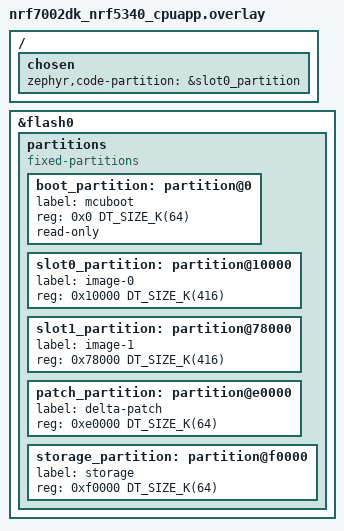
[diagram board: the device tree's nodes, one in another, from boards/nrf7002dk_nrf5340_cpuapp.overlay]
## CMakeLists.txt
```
# SPDX-License-Identifier: Apache-2.0

cmake_minimum_required(VERSION 3.20.0)

find_package(Zephyr REQUIRED HINTS $ENV{ZEPHYR_BASE})
project(delta)

target_sources(app PRIVATE src/main.c)
target_sources_ifndef(CONFIG_DELTA_SAMPLE_TARGET_MODE app PRIVATE src/delta_apply.c)

# flash_patch target: convert a patch binary to Intel HEX at the
# devicetree-resolved patch_partition address and flash it.
dt_nodelabel(patch_path NODELABEL "patch_partition")
if(DEFINED patch_path)
  dt_reg_addr(patch_offset PATH ${patch_path})

  math(EXPR PATCH_FLASH_ADDR
       "${CONFIG_FLASH_BASE_ADDRESS} + ${patch_offset}"
       OUTPUT_FORMAT HEXADECIMAL)

  set(PATCH_FILE ${CMAKE_CURRENT_SOURCE_DIR}/firmwares/patch.bin
      CACHE FILEPATH "Path to the delta patch binary to flash")

  find_program(WEST west REQUIRED)

  add_custom_target(flash_patch
      COMMAND ${CMAKE_OBJCOPY} -I binary -O ihex
              --change-addresses ${PATCH_FLASH_ADDR}
              ${PATCH_FILE}
              ${PROJECT_BINARY_DIR}/patch.hex
      COMMAND ${WEST} flash --hex-file ${PROJECT_BINARY_DIR}/patch.hex
      COMMENT "Flashing delta patch to patch_partition at ${PATCH_FLASH_ADDR}"
      USES_TERMINAL
  )
endif()
```

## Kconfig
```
# Copyright (c) 2026 Clovis Corde
# SPDX-License-Identifier: Apache-2.0

mainmenu "Delta Firmware Update Sample"

source "Kconfig.zephyr"

config DELTA_SAMPLE_TARGET_MODE
	bool "Build as the target firmware for delta patch generation"
	help
	  When enabled, the application simply prints a message and
	  exits without applying any delta patch. This is used to
	  produce the target firmware binary needed by
	  generate_patch.py to compute the delta between the source
	  and target images.
```

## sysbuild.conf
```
SB_CONFIG_BOOTLOADER_MCUBOOT=y
SB_CONFIG_MCUBOOT_MODE_SWAP_USING_MOVE=y
```

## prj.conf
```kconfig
# Logging
CONFIG_LOG=y
CONFIG_LOG_MODE_DEFERRED=y

CONFIG_MAIN_STACK_SIZE=8192
CONFIG_REBOOT=y

# Flash / MCUboot
CONFIG_FLASH=y
CONFIG_FLASH_MAP=y
CONFIG_STREAM_FLASH=y
CONFIG_IMG_MANAGER=y
CONFIG_MCUBOOT_IMG_MANAGER=y
CONFIG_BOOTLOADER_MCUBOOT=y
CONFIG_IMG_BLOCK_BUF_SIZE=512

# Delta patching library + bsdiff/heatshrink backend
CONFIG_DELTA=y
CONFIG_DELTA_BACKEND_BSDIFFHS=y
CONFIG_DELTA_LOG_LEVEL_INF=y

# heatshrink in static-allocation mode; the patch must declare a
# window_sz2 and lookahead_sz2 with these values.
CONFIG_HEATSHRINK=y
CONFIG_HEATSHRINK_STATIC_WINDOW_BITS=10
CONFIG_HEATSHRINK_STATIC_LOOKAHEAD_BITS=4
CONFIG_HEATSHRINK_STATIC_INPUT_BUFFER_SIZE=64
```

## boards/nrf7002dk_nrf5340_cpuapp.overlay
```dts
/*
 * Copyright (c) 2026 Clovis Corde
 * SPDX-License-Identifier: Apache-2.0
 */

/ {
	chosen {
		zephyr,code-partition = &slot0_partition;
	};
};

&flash0 {
	/delete-node/ partitions;

	partitions {
		compatible = "fixed-partitions";
		#address-cells = <1>;
		#size-cells = <1>;

		boot_partition: partition@0 {
			label = "mcuboot";
			reg = <0x0 DT_SIZE_K(64)>;
			read-only;
		};

		slot0_partition: partition@10000 {
			label = "image-0";
			reg = <0x10000 DT_SIZE_K(416)>;
		};

		slot1_partition: partition@78000 {
			label = "image-1";
			reg = <0x78000 DT_SIZE_K(416)>;
		};

		patch_partition: partition@e0000 {
			label = "delta-patch";
			reg = <0xe0000 DT_SIZE_K(64)>;
		};

		storage_partition: partition@f0000 {
			label = "storage";
			reg = <0xf0000 DT_SIZE_K(64)>;
		};
	};
};
```

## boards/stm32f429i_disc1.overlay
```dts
/*
 * Copyright (c) 2026 Clovis Corde
 * SPDX-License-Identifier: Apache-2.0
 */

/ {
	chosen {
		zephyr,code-partition = &slot0_partition;
	};
};

&flash0 {
	partitions {
		compatible = "fixed-partitions";
		#address-cells = <1>;
		#size-cells = <1>;

		boot_partition: partition@0 {
			label = "mcuboot";
			reg = <0x0 DT_SIZE_K(128)>;
			read-only;
		};

		slot0_partition: partition@20000 {
			label = "image-0";
			reg = <0x20000 DT_SIZE_K(384)>;
		};

		slot1_partition: partition@80000 {
			label = "image-1";
			reg = <0x80000 DT_SIZE_K(384)>;
		};

		patch_partition: partition@120000 {
			label = "delta-patch";
			reg = <0x120000 DT_SIZE_K(128)>;
		};
	};
};
```

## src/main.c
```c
/*
 * Copyright (c) 2026 Clovis Corde
 *
 * SPDX-License-Identifier: Apache-2.0
 */

#include <zephyr/kernel.h>
#include <zephyr/logging/log.h>

#if !defined(CONFIG_DELTA_SAMPLE_TARGET_MODE)
#include "delta_apply.h"
#endif

LOG_MODULE_REGISTER(delta_sample, LOG_LEVEL_INF);

int main(void)
{
#if defined(CONFIG_DELTA_SAMPLE_TARGET_MODE)
	LOG_INF("Delta target firmware");
	return 0;
#else
	int ret;

	LOG_INF("Delta sample");

	ret = delta_apply_and_reboot();
	if (ret != 0) {
		LOG_ERR("Error while applying delta update: %d", ret);
	}

	return ret;
#endif
}
```

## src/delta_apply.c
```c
/*
 * Copyright (c) 2026 Clovis Corde
 *
 * SPDX-License-Identifier: Apache-2.0
 */

#include <zephyr/delta/delta.h>
#include <zephyr/delta/backend_bsdiffhs.h>
#include <zephyr/dfu/flash_img.h>
#include <zephyr/dfu/mcuboot.h>
#include <zephyr/kernel.h>
#include <zephyr/logging/log.h>
#include <zephyr/logging/log_ctrl.h>
#include <zephyr/storage/flash_map.h>
#include <zephyr/sys/reboot.h>
#include <zephyr/sys/util.h>

#include "delta_apply.h"

LOG_MODULE_REGISTER(delta_apply, LOG_LEVEL_INF);

/* Glue between lib/delta and the MCUboot flash layout. */
struct delta_ctx {
	const struct flash_area *source_area;
	const struct flash_area *patch_area;
	struct flash_img_context flash_img;
};

/* Patch read-ahead window handed to the backend. */
#define WORK_BUF_SIZE 128

static uint8_t work_buf[WORK_BUF_SIZE];

static int read_source(void *vctx, size_t off, void *buf, size_t len)
{
	struct delta_ctx *ctx = vctx;

	return flash_area_read(ctx->source_area, (off_t)off, buf, len);
}

static int read_patch(void *vctx, size_t off, void *buf, size_t len)
{
	struct delta_ctx *ctx = vctx;

	return flash_area_read(ctx->patch_area, (off_t)off, buf, len);
}

static int write_target(void *vctx, size_t off, const void *buf, size_t len)
{
	struct delta_ctx *ctx = vctx;

	ARG_UNUSED(off);
	return flash_img_buffered_write(&ctx->flash_img, buf, len, false);
}

static int finalize_target(void *vctx)
{
	struct delta_ctx *ctx = vctx;

	/* Flush the last partially filled block to the upload slot. */
	return flash_img_buffered_write(&ctx->flash_img, NULL, 0, true);
}

int delta_apply_and_reboot(void)
{
	struct delta_ctx ctx;
	int ret;

	ret = flash_area_open(PARTITION_ID(slot0_partition), &ctx.source_area);
	if (ret != 0) {
		LOG_ERR("flash_area_open(slot0) failed: %d", ret);
		return ret;
	}

	ret = flash_area_open(PARTITION_ID(patch_partition), &ctx.patch_area);
	if (ret != 0) {
		LOG_ERR("flash_area_open(patch) failed: %d", ret);
		flash_area_close(ctx.source_area);
		return ret;
	}

	ret = flash_img_init(&ctx.flash_img);
	if (ret != 0) {
		LOG_ERR("flash_img_init failed: %d", ret);
		flash_area_close(ctx.patch_area);
		flash_area_close(ctx.source_area);
		return ret;
	}

	struct delta_io io = {
		.read_source = read_source,
		.read_patch = read_patch,
		.write_target = write_target,
		.finalize = finalize_target,
		.ctx = &ctx,
	};
	struct delta_config cfg = {
		.work_buf = work_buf,
		.work_sz = sizeof(work_buf),
		.source_size = ctx.source_area->fa_size,
		.patch_size = ctx.patch_area->fa_size,
		.max_target_size = ctx.flash_img.flash_area->fa_size,
	};

	ret = delta_apply_patch(&io, &delta_backend_bsdiffhs, &cfg);

	flash_area_close(ctx.patch_area);
	flash_area_close(ctx.source_area);
	if (ret != 0) {
		LOG_ERR("delta apply failed: %d", ret);
		return ret;
	}

	ret = boot_request_upgrade(BOOT_UPGRADE_TEST);
	if (ret != 0) {
		LOG_ERR("boot_request_upgrade failed: %d", ret);
		return ret;
	}

	LOG_INF("New firmware written, rebooting...");
	LOG_PANIC();
	sys_reboot(SYS_REBOOT_COLD);

	return 0;
}
```

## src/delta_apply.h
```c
/*
 * Copyright (c) 2026 Clovis Corde
 *
 * SPDX-License-Identifier: Apache-2.0
 */
#ifndef DELTA_APPLY_H_
#define DELTA_APPLY_H_

/**
 * @brief Read the patch from patch_partition, apply it to the upload slot,
 *        mark the new image for upgrade, and reboot.
 *
 * @retval 0 on success (does not return, reboots on success).
 * @retval Negative errno on failure.
 */
int delta_apply_and_reboot(void);

#endif /* DELTA_APPLY_H_ */
```
